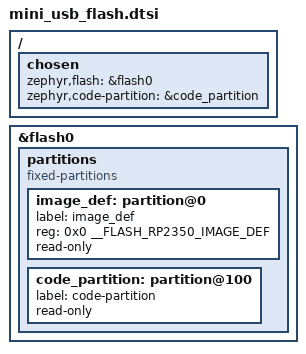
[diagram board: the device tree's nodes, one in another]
/*
 * Copyright (c) 2025 TiaC Systems
 * SPDX-License-Identifier: Apache-2.0
 */

#define __FLASH_RP2350_IMAGE_DEF	0x100

/ {
	chosen {
		zephyr,flash = &flash0;
		zephyr,code-partition = &code_partition;
	};
};

&flash0 {
	partitions {
		compatible = "fixed-partitions";
		#address-cells = <1>;
		#size-cells = <1>;

		/* Reserved memory for the second stage bootloader */
		image_def: partition@0 {
			label = "image_def";
			reg = <0x0 __FLASH_RP2350_IMAGE_DEF>;
			read-only;
		};

		/*
		 * Usable flash. Starts at 0x100, after the second stage
		 * bootloader. The partition size is 4MB minus the 0x100
		 * bytes taken by the second stage bootloader.
		 */
		code_partition: partition@100 {
			label = "code-partition";
			read-only;
		};
	};
};
